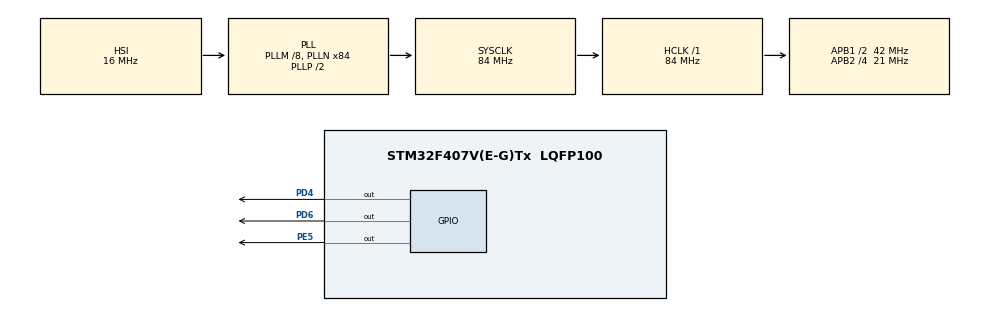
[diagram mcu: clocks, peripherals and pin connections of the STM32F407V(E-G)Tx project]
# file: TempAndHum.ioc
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Mcu.Family=STM32F4
Mcu.Name=STM32F407V(E-G)Tx
Mcu.Package=LQFP100
NVIC.PriorityGroup=NVIC_PRIORITYGROUP_0
PD4.GPIO_ModeDefaultOutputPP=GPIO_MODE_OUTPUT_OD
PD4.GPIO_PuPd=GPIO_PULLUP
PD4.Signal=GPIO_Output
PD6.GPIO_ModeDefaultOutputPP=GPIO_MODE_OUTPUT_OD
PD6.GPIO_PuPd=GPIO_PULLUP
PD6.Signal=GPIO_Output
PE5.Signal=GPIO_Output
ProjectManager.HeapSize=0x200
ProjectManager.StackSize=0x400
ProjectManager.TargetToolchain=STM32CubeIDE
RCC.48MHZClocksFreq_Value=24000000
RCC.AHBFreq_Value=84000000
RCC.APB1CLKDivider=RCC_HCLK_DIV2
RCC.APB1Freq_Value=42000000
RCC.APB1TimFreq_Value=84000000
RCC.APB2CLKDivider=RCC_HCLK_DIV4
RCC.APB2Freq_Value=21000000
RCC.APB2TimFreq_Value=42000000
RCC.CortexFreq_Value=84000000
RCC.HCLKFreq_Value=84000000
RCC.HSE_VALUE=8000000
RCC.HSI_VALUE=16000000
RCC.PLLM=8
RCC.PLLN=84
RCC.PLLQ=7
RCC.SYSCLKFreq_VALUE=84000000
RCC.SYSCLKSource=RCC_SYSCLKSOURCE_PLLCLK
RCC.VCOOutputFreq_Value=168000000
TIM1.Prescaler=83
VP_TIM1_VS_ClockSourceINT.Mode=Internal
board=STM32F407G-DISC1

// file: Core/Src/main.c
/* USER CODE BEGIN Header */
/**
  ******************************************************************************
  * @file           : main.c
  * @brief          : Main program body
  ******************************************************************************
  * @attention
  *
  * Copyright (c) 2026 STMicroelectronics.
  * All rights reserved.
  *
  * This software is licensed under terms that can be found in the LICENSE file
  * in the root directory of this software component.
  * If no LICENSE file comes with this software, it is provided AS-IS.
  *
  ******************************************************************************
  */
/* USER CODE END Header */
#include "main.h"
#include "stdio.h"
#include "tm1637.h"

/* USER CODE BEGIN PTD */
#define dht_port GPIOE
#define dht_pin GPIO_PIN_5
/* USER CODE END PTD */

TIM_HandleTypeDef htim1;

/* USER CODE BEGIN PV */
uint8_t RHI, RHD, TCI, TCD, SUM;
uint32_t pMillis, cMillis;
float tCelsius = 0;
float RH = 0;
char info[36] = {0};
/* USER CODE END PV */

void SystemClock_Config(void);
static void MX_GPIO_Init(void);
static void MX_TIM1_Init(void);

/* USER CODE BEGIN 0 */
void microDelay(uint16_t delay) {
  __HAL_TIM_SET_COUNTER(&htim1, 0);
  while (__HAL_TIM_GET_COUNTER(&htim1) < delay);
}

uint8_t dht11_init(void) {
  uint8_t Response = 1;
  GPIO_InitTypeDef GPIO_InitStruct = {0};

  GPIO_InitStruct.Pin = dht_pin;
  GPIO_InitStruct.Mode = GPIO_MODE_OUTPUT_PP;
  GPIO_InitStruct.Speed = GPIO_SPEED_FREQ_LOW;
  GPIO_InitStruct.Pull = GPIO_NOPULL;
  HAL_GPIO_Init(dht_port, &GPIO_InitStruct);

  HAL_GPIO_WritePin(dht_port, dht_pin, 0);
  HAL_Delay(20);
  HAL_GPIO_WritePin(dht_port, dht_pin, 1);
  microDelay(30);

  GPIO_InitStruct.Mode = GPIO_MODE_INPUT;
  GPIO_InitStruct.Pull = GPIO_PULLUP;
  HAL_GPIO_Init(dht_port, &GPIO_InitStruct);
  microDelay(40);

  if (!HAL_GPIO_ReadPin(dht_port, dht_pin)) {
    microDelay(80);
    if (HAL_GPIO_ReadPin(dht_port, dht_pin)) Response = 1;
  }

  pMillis = HAL_GetTick();

  while (HAL_GPIO_ReadPin(dht_port, dht_pin) && (HAL_GetTick() - pMillis < 2));
  return Response;
}

uint8_t dht11_read(void) {
  uint8_t a, b = 0;
  for (a = 0; a < 8; a++) {
    pMillis = HAL_GetTick();

    while (!HAL_GPIO_ReadPin(dht_port, dht_pin) && (HAL_GetTick() - pMillis < 2));
    microDelay(40);

    if (HAL_GPIO_ReadPin(dht_port, dht_pin))
      b |= (1 << (7 - a));
    while (HAL_GPIO_ReadPin(dht_port, dht_pin) && (HAL_GetTick() - pMillis < 2));
  }
  return b;
}
/* USER CODE END 0 */

int main(void)
{

  /* MCU Configuration--------------------------------------------------------*/

  /* Reset of all peripherals, Initializes the Flash interface and the Systick. */
  HAL_Init();

  /* Configure the system clock */
  SystemClock_Config();

  /* Initialize all configured peripherals */
  MX_GPIO_Init();
  MX_TIM1_Init();
  /* USER CODE BEGIN 2 */
  HAL_TIM_Base_Start(&htim1);
  TM1637_Init(GPIOD, GPIO_PIN_6, GPIOD, GPIO_PIN_4);

  /* USER CODE END 2 */

  /* Infinite loop */
  /* USER CODE BEGIN WHILE */
  while (1)
  {
	  if (dht11_init()) {
	         RHI = dht11_read();
	         RHD = dht11_read();
	         TCI = dht11_read();
	         TCD = dht11_read();
	         SUM = dht11_read();

	         if (RHI + RHD + TCI + TCD == SUM) {
	             tCelsius = (float)TCI + (float)(TCD / 10.0);
	             RH = (float)RHI + (float)(RHD / 10.0);
	         }
	     }

	     TM1637_DisplayNumber((int16_t)tCelsius);
	     HAL_Delay(1000);
	     TM1637_DisplayNumber((int16_t)RH);
	     HAL_Delay(1000);
    /* USER CODE END WHILE */

  }
}

void SystemClock_Config(void)
{
  RCC_OscInitTypeDef RCC_OscInitStruct = {0};
  RCC_ClkInitTypeDef RCC_ClkInitStruct = {0};

  /** Configure the main internal regulator output voltage
  */
  __HAL_RCC_PWR_CLK_ENABLE();
  __HAL_PWR_VOLTAGESCALING_CONFIG(PWR_REGULATOR_VOLTAGE_SCALE1);

  /** Initializes the RCC Oscillators according to the specified parameters
  * in the RCC_OscInitTypeDef structure.
  */
  RCC_OscInitStruct.OscillatorType = RCC_OSCILLATORTYPE_HSI;
  RCC_OscInitStruct.HSIState = RCC_HSI_ON;
  RCC_OscInitStruct.HSICalibrationValue = RCC_HSICALIBRATION_DEFAULT;
  RCC_OscInitStruct.PLL.PLLState = RCC_PLL_ON;
  RCC_OscInitStruct.PLL.PLLSource = RCC_PLLSOURCE_HSI;
  RCC_OscInitStruct.PLL.PLLM = 8;
  RCC_OscInitStruct.PLL.PLLN = 84;
  RCC_OscInitStruct.PLL.PLLP = RCC_PLLP_DIV2;
  RCC_OscInitStruct.PLL.PLLQ = 7;
  if (HAL_RCC_OscConfig(&RCC_OscInitStruct) != HAL_OK)
  {
    Error_Handler();
  }

  /** Initializes the CPU, AHB and APB buses clocks
  */
  RCC_ClkInitStruct.ClockType = RCC_CLOCKTYPE_HCLK|RCC_CLOCKTYPE_SYSCLK
                              |RCC_CLOCKTYPE_PCLK1|RCC_CLOCKTYPE_PCLK2;
  RCC_ClkInitStruct.SYSCLKSource = RCC_SYSCLKSOURCE_PLLCLK;
  RCC_ClkInitStruct.AHBCLKDivider = RCC_SYSCLK_DIV1;
  RCC_ClkInitStruct.APB1CLKDivider = RCC_HCLK_DIV2;
  RCC_ClkInitStruct.APB2CLKDivider = RCC_HCLK_DIV4;

  if (HAL_RCC_ClockConfig(&RCC_ClkInitStruct, FLASH_LATENCY_2) != HAL_OK)
  {
    Error_Handler();
  }
}

static void MX_TIM1_Init(void)
{

  TIM_ClockConfigTypeDef sClockSourceConfig = {0};
  TIM_MasterConfigTypeDef sMasterConfig = {0};

  htim1.Instance = TIM1;
  htim1.Init.Prescaler = 83;
  htim1.Init.CounterMode = TIM_COUNTERMODE_UP;
  htim1.Init.Period = 65535;
  htim1.Init.ClockDivision = TIM_CLOCKDIVISION_DIV1;
  htim1.Init.RepetitionCounter = 0;
  htim1.Init.AutoReloadPreload = TIM_AUTORELOAD_PRELOAD_DISABLE;
  if (HAL_TIM_Base_Init(&htim1) != HAL_OK)
  {
    Error_Handler();
  }
  sClockSourceConfig.ClockSource = TIM_CLOCKSOURCE_INTERNAL;
  if (HAL_TIM_ConfigClockSource(&htim1, &sClockSourceConfig) != HAL_OK)
  {
    Error_Handler();
  }
  sMasterConfig.MasterOutputTrigger = TIM_TRGO_RESET;
  sMasterConfig.MasterSlaveMode = TIM_MASTERSLAVEMODE_DISABLE;
  if (HAL_TIMEx_MasterConfigSynchronization(&htim1, &sMasterConfig) != HAL_OK)
  {
    Error_Handler();
  }

}

static void MX_GPIO_Init(void)
{
  GPIO_InitTypeDef GPIO_InitStruct = {0};

  /* GPIO Ports Clock Enable */
  __HAL_RCC_GPIOE_CLK_ENABLE();
  __HAL_RCC_GPIOD_CLK_ENABLE();

  /*Configure GPIO pin Output Level */
  HAL_GPIO_WritePin(GPIOE, GPIO_PIN_5, GPIO_PIN_RESET);

  /*Configure GPIO pin Output Level */
  HAL_GPIO_WritePin(GPIOD, GPIO_PIN_4|GPIO_PIN_6, GPIO_PIN_RESET);

  /*Configure GPIO pin : PE5 */
  GPIO_InitStruct.Pin = GPIO_PIN_5;
  GPIO_InitStruct.Mode = GPIO_MODE_OUTPUT_PP;
  GPIO_InitStruct.Pull = GPIO_NOPULL;
  GPIO_InitStruct.Speed = GPIO_SPEED_FREQ_LOW;
  HAL_GPIO_Init(GPIOE, &GPIO_InitStruct);

  /*Configure GPIO pins : PD4 PD6 */
  GPIO_InitStruct.Pin = GPIO_PIN_4|GPIO_PIN_6;
  GPIO_InitStruct.Mode = GPIO_MODE_OUTPUT_OD;
  GPIO_InitStruct.Pull = GPIO_PULLUP;
  GPIO_InitStruct.Speed = GPIO_SPEED_FREQ_LOW;
  HAL_GPIO_Init(GPIOD, &GPIO_InitStruct);

}

void Error_Handler(void)
{
  __disable_irq();
  while (1)
  {
  }
}
